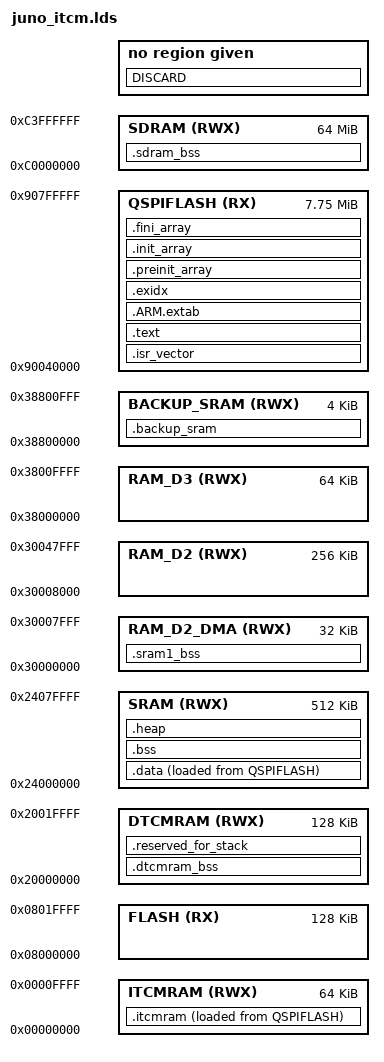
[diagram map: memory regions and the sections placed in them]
/* Generated by LinkerScriptGenerator [http://visualgdb.com/tools/LinkerScriptGenerator]
 * Target: STM32H750IB
 * The file is provided under the BSD license.
 * yeah okay but i also modified it a lot so like, give me some credit too mr BSD
 */

ENTRY(Reset_Handler)

MEMORY
{
	FLASH       (RX)  : ORIGIN = 0x08000000, LENGTH = 128K
	DTCMRAM     (RWX) : ORIGIN = 0x20000000, LENGTH = 128K
	SRAM        (RWX) : ORIGIN = 0x24000000, LENGTH = 512K
	RAM_D2_DMA  (RWX) : ORIGIN = 0x30000000, LENGTH = 32K
	RAM_D2      (RWX) : ORIGIN = 0x30008000, LENGTH = 256K
	RAM_D3      (RWX) : ORIGIN = 0x38000000, LENGTH = 64K
	BACKUP_SRAM (RWX) : ORIGIN = 0x38800000, LENGTH = 4K
	ITCMRAM     (RWX) : ORIGIN = 0x00000000, LENGTH = 64K
	SDRAM       (RWX) : ORIGIN = 0xc0000000, LENGTH = 64M
	QSPIFLASH   (RX)  : ORIGIN = 0x90040000, LENGTH = 7936K
}

_estack = 0x20020000;

SECTIONS
{
	.isr_vector :
	{
		. = ALIGN(4);
		KEEP(*(.isr_vector))
		. = ALIGN(4);
	} > QSPIFLASH

	/* PLACEMENT A/B, INSIDE ONE BOOT.
	 *
	 * The *_itcm.o objects are SECOND COMPILATIONS of src/voice_render.c and
	 * src/master_render.c (see daisy/voice_render_itcm.c). Only those copies
	 * live here; the ORIGINAL voice_render.o / master_render.o stay in .text
	 * below and execute XIP from QSPI. Both placements therefore exist in the
	 * same image at once, and the firmware picks between them at run time
	 * through juno_voice_render_fn / juno_master_render_fn. The old scheme
	 * needed two images and two flashes to learn the same thing.
	 *
	 * The glob is anchored on the _itcm suffix: `*voice_render.o` would ALSO
	 * match voice_render_itcm.o, which would silently move the baseline arm
	 * into ITCM and make the A/B compare ITCM against ITCM.
	 *
	 * juno_dsp.o and juno_ftz.o deliberately stay in QSPI in BOTH arms. They
	 * are shared by both copies, so relocating them would change the baseline
	 * too and there would be no baseline left. The consequence must be stated
	 * when the numbers are read: the ITCM arms are a LOWER BOUND on what full
	 * placement buys, because their helper calls still fetch from QSPI.
	 *
	 * Load address stays in QSPI; main() copies the bytes to ITCM before
	 * anything calls them. Placed BEFORE .text so these objects are claimed
	 * here and are not also emitted there. */
	.itcmram :
	{
		. = ALIGN(4);
		_sitcm = .;
		_svoice_itcm = .;
		*voice_render_itcm.o(.text .text*)
		. = ALIGN(4);
		_evoice_itcm = .;
		_smaster_itcm = .;
		*master_render_itcm.o(.text .text*)
		. = ALIGN(4);
		_emaster_itcm = .;
		. = ALIGN(4);
		_eitcm = .;
	} > ITCMRAM AT > QSPIFLASH
	_siitcm = LOADADDR(.itcmram);

	.text :
	{
		. = ALIGN(4);
		_stext = .;

		*(.text)
		*(.text*)
		*(.rodata)
		*(.rodata*)
		*(.glue_7)
		*(.glue_7t)
		KEEP(*(.init))
		KEEP(*(.fini))
		. = ALIGN(4);
		_etext = .;

	} > QSPIFLASH

	.ARM.extab :
	{
		. = ALIGN(4);
		*(.ARM.extab)
		*(.gnu.linkonce.armextab.*)
		. = ALIGN(4);
	} > QSPIFLASH

	.exidx :
	{
		. = ALIGN(4);
		PROVIDE(__exidx_start = .);
		*(.ARM.exidx*)
		. = ALIGN(4);
		PROVIDE(__exidx_end = .);
	} > QSPIFLASH

	.ARM.attributes 0 : { *(.ARM.attributes) }

	.preinit_array :
	{
		PROVIDE_HIDDEN(__preinit_array_start = .);
		KEEP(*(.preinit_array*))
		PROVIDE_HIDDEN(__preinit_array_end = .);
	} > QSPIFLASH

	.init_array :
	{
		PROVIDE_HIDDEN(__init_array_start = .);
		KEEP(*(SORT(.init_array.*)))
		KEEP(*(.init_array*))
		PROVIDE_HIDDEN(__init_array_end = .);
	} > QSPIFLASH

	.fini_array :
	{
		PROVIDE_HIDDEN(__fini_array_start = .);
		KEEP(*(.fini_array*))
		KEEP(*(SORT(.fini_array.*)))
		PROVIDE_HIDDEN(__fini_array_end = .);
	} > QSPIFLASH

	.sram1_bss (NOLOAD) :
	{
		. = ALIGN(4);
		_ssram1_bss = .;

		PROVIDE(__sram1_bss_start__ = _sram1_bss);
		*(.sram1_bss)
		*(.sram1_bss*)
		. = ALIGN(4);
		_esram1_bss = .;

		PROVIDE(__sram1_bss_end__ = _esram1_bss);
	} > RAM_D2_DMA

	.data :
	{
		. = ALIGN(4);
		_sdata = .;

		PROVIDE(__data_start__ = _sdata);
		*(.data)
		*(.data*)
		. = ALIGN(4);
		_edata = .;

		PROVIDE(__data_end__ = _edata);
	} > SRAM AT > QSPIFLASH

	_sidata = LOADADDR(.data);

	.bss (NOLOAD) :
	{
		. = ALIGN(4);
		_sbss = .;

		PROVIDE(__bss_start__ = _sbss);
		*(.bss)
		*(.bss*)
		*(COMMON)
		. = ALIGN(4);
		_ebss = .;

		PROVIDE(__bss_end__ = _ebss);
	} > SRAM

	.dtcmram_bss (NOLOAD) :
	{
		. = ALIGN(4);
		_sdtcmram_bss = .;

		PROVIDE(__dtcmram_bss_start__ = _sdtcmram_bss);
		*(.dtcmram_bss)
		*(.dtcmram_bss*)
		. = ALIGN(4);
		_edtcmram_bss = .;

		PROVIDE(__dtcmram_bss_end__ = _edtcmram_bss);
	} > DTCMRAM

	/*
	.sdram_text :
	{
		. = ALIGN(4);
		_ssdram_text = .;

		PROVIDE(__sdram_text_start = _ssdram_text);
		*(.sdram_text)
		*(.sdram_text*)
		. = ALIGN(4);
		_esdram_text = .;

		PROVIDE(__sdram_text_end = _esdram_text);
	} > SDRAM AT >FLASH
	_sisdram_text = LOADADDR(.sdram_text);
	*/

	.sdram_bss (NOLOAD) :
	{
		. = ALIGN(4);
		_ssdram_bss = .;

		PROVIDE(__sdram_bss_start = _ssdram_bss);
		*(.sdram_bss)
		*(.sdram_bss*)
		. = ALIGN(4);
		_esdram_bss = .;

		PROVIDE(__sdram_bss_end = _esdram_bss);
	} > SDRAM

	.backup_sram (NOLOAD) :
	{
		. = ALIGN(4);
		_sbackup_sram = .;

		PROVIDE(__backup_sram_start = _sbackup_sram);
		*(.backup_sram)
		*(.backup_sram*)
		. = ALIGN(4);
		_ebackup_sram = .;

		PROVIDE(__backup_sram_end = _ebackup_sram);
	} > BACKUP_SRAM


    /* .qspiflash_text :
	{
		. = ALIGN(4);
		_sqspiflash_text = .;

		PROVIDE(__qspiflash_text_start = _sqspiflash_text);
		*(.qspiflash_text)
		*(.qspiflash_text*)
		. = ALIGN(4);
		_eqspiflash_text = .;

		PROVIDE(__qspiflash_text_end = _eqspiflash_text);
	} > QSPIFLASH

	.qspiflash_data :
	{
		. = ALIGN(4);
		_sqspiflash_data = .;

		PROVIDE(__qspiflash_data_start = _sqspiflash_data);
		*(.qspiflash_data)
		*(.qspiflash_data*)
		. = ALIGN(4);
		_eqspiflash_data = .;

		PROVIDE(__qspiflash_data_end = _eqspiflash_data);
	} > QSPIFLASH

	.qspiflash_bss (NOLOAD) :
	{
		. = ALIGN(4);
		_sqspiflash_bss = .;

		PROVIDE(__qspiflash_bss_start = _sqspiflash_bss);
		*(.qspiflash_bss)
		*(.qspiflash_bss*)
		. = ALIGN(4);
		_eqspiflash_bss = .;

		PROVIDE(__qspiflash_bss_end = _eqspiflash_bss);
	} > QSPIFLASH */

	.heap (NOLOAD) :
	{
		. = ALIGN(4);
		PROVIDE(__heap_start__ = .);
		PROVIDE(__heap_start = .);
		KEEP(*(.heap))
		. = ALIGN(4);
		PROVIDE(__heap_end = .);
		PROVIDE(__heap_end__ = .);
	} > SRAM

	PROVIDE(end = .);

	.reserved_for_stack (NOLOAD) :
	{
		. = ALIGN(4);
		PROVIDE(__reserved_for_stack_start__ = .);
		KEEP(*(.reserved_for_stack))
		. = ALIGN(4);
		PROVIDE(__reserved_for_stack_end__ = .);
	} > DTCMRAM

    DISCARD :
    {
        libc.a ( * )
        libm.a ( * )
        libgcc.a ( * )
    }

}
